VERSION ""

NS_ :

BS_:

BU_: XXX

BO_ 85 CID_ORPMJI: 8 XXX
 SG_ sig_kpehwq : 40|1@1+ (1,0) [0|1] "" XXX
 SG_ sig_occrqr : 56|8@1+ (1,0) [0|255] "" XXX

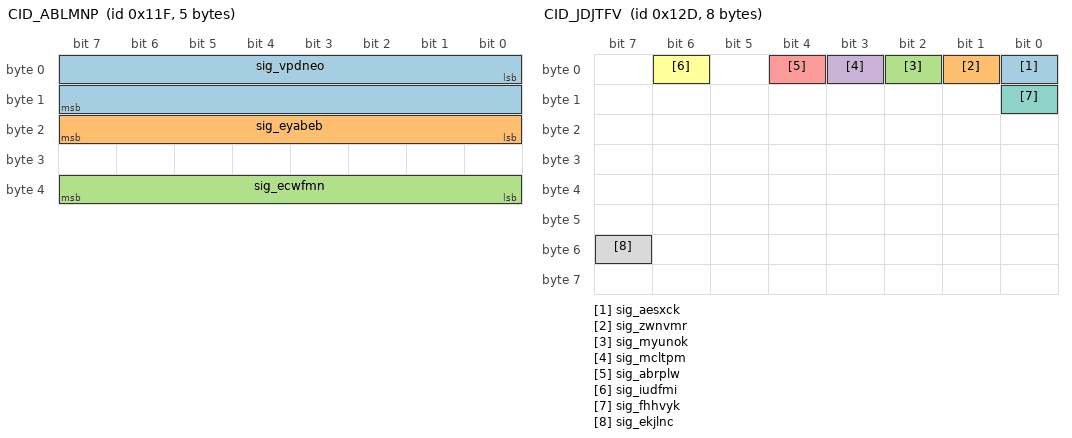
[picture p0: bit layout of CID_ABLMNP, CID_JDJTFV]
BO_ 287 CID_ABLMNP: 5 XXX
 SG_ sig_vpdneo : 0|16@1- (0.1,0) [-450|450] "" XXX
 SG_ sig_eyabeb : 16|8@1+ (4,0) [0|1020] "" XXX
 SG_ sig_ecwfmn : 32|8@1+ (1,0) [0|255] "" XXX

BO_ 289 CID_XTCXCM: 8 XXX
 SG_ sig_tqkhlx : 0|12@1+ (1,0) [0|255] "" XXX

BO_ 301 CID_JDJTFV: 8 XXX
 SG_ sig_aesxck : 0|1@0+ (1,0) [0|1] "" XXX
 SG_ sig_zwnvmr : 1|1@0+ (1,0) [0|1] "" XXX
 SG_ sig_myunok : 2|1@0+ (1,0) [0|1] "" XXX
 SG_ sig_mcltpm : 3|1@0+ (1,0) [0|1] "" XXX
 SG_ sig_abrplw : 4|1@0+ (1,0) [0|1] "" XXX
 SG_ sig_iudfmi : 6|1@0+ (1,0) [0|1] "" XXX
 SG_ sig_fhhvyk : 8|1@0+ (1,0) [0|1] "" XXX
 SG_ sig_ekjlnc : 55|1@0+ (1,0) [0|1] "" XXX

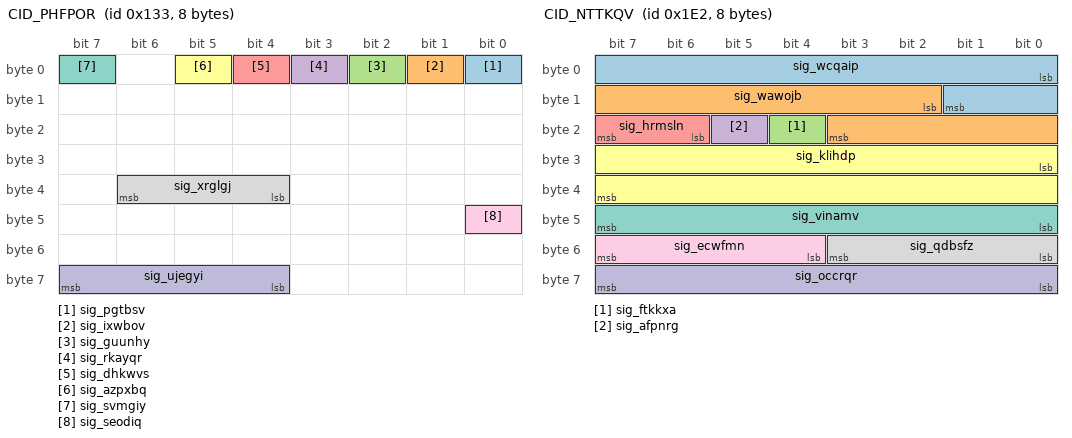
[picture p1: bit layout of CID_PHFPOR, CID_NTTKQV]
BO_ 307 CID_PHFPOR: 8 XXX
 SG_ sig_pgtbsv : 0|1@0+ (1,0) [0|1] "" XXX
 SG_ sig_ixwbov : 1|1@1+ (1,0) [0|1] "" XXX
 SG_ sig_guunhy : 2|1@1+ (1,0) [0|1] "" XXX
 SG_ sig_rkayqr : 3|1@1+ (1,0) [0|1] "" XXX
 SG_ sig_dhkwvs : 4|1@0+ (1,0) [0|1] "" XXX
 SG_ sig_azpxbq : 5|1@0+ (1,0) [0|1] "" XXX
 SG_ sig_svmgiy : 7|1@0+ (1,0) [0|1] "" XXX
 SG_ sig_xrglgj : 36|3@1+ (1,0) [0|7] "" XXX
 SG_ sig_seodiq : 40|1@0+ (1,0) [0|1] "" XXX
 SG_ sig_ujegyi : 63|4@0+ (1,0) [0|15] "" XXX

BO_ 482 CID_NTTKQV: 8 XXX
 SG_ sig_wcqaip : 0|10@1- (0.01,0) [0|5] "" XXX
 SG_ sig_wawojb : 10|10@1- (0.01,0) [-5|0] "" XXX
 SG_ sig_ftkkxa : 20|1@0+ (1,0) [0|1] "" XXX
 SG_ sig_afpnrg : 21|1@0+ (1,0) [0|1] "" XXX
 SG_ sig_hrmsln : 22|2@1+ (1,0) [0|1] "" XXX
 SG_ sig_klihdp : 24|16@1- (0.1,0) [-780|779.9] "" XXX
 SG_ sig_vinamv : 47|8@0+ (1,0) [0|255] "" XXX
 SG_ sig_qdbsfz : 48|4@1+ (1,0) [0|15] "" XXX
 SG_ sig_ecwfmn : 52|4@1+ (1,0) [0|15] "" XXX
 SG_ sig_occrqr : 56|8@1+ (1,0) [0|255] "" XXX

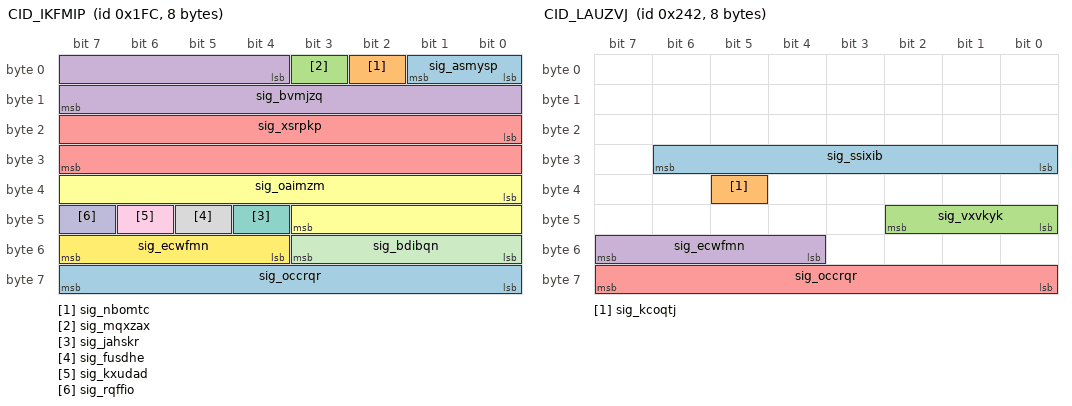
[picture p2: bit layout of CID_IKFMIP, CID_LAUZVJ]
BO_ 508 CID_IKFMIP: 8 XXX
 SG_ sig_asmysp : 0|2@1+ (1,0) [0|1] "" XXX
 SG_ sig_nbomtc : 2|1@1+ (1,0) [0|1] "" XXX
 SG_ sig_mqxzax : 3|1@0+ (1,0) [0|1] "" XXX
 SG_ sig_bvmjzq : 4|12@1- (1,0) [-2048|2047] "" XXX
 SG_ sig_xsrpkp : 16|16@1- (0.1,0) [-780|779.9] "Deg" XXX
 SG_ sig_oaimzm : 32|12@1- (1,0) [0|63] "" XXX
 SG_ sig_jahskr : 44|1@0+ (1,0) [0|1] "" XXX
 SG_ sig_fusdhe : 45|1@1+ (1,0) [0|255] "" XXX
 SG_ sig_kxudad : 46|1@1+ (1,0) [0|1] "" XXX
 SG_ sig_rqffio : 47|1@0+ (1,0) [0|3] "" XXX
 SG_ sig_bdibqn : 48|4@1+ (1,0) [0|15] "" XXX
 SG_ sig_ecwfmn : 52|4@1+ (1,0) [0|15] "" XXX
 SG_ sig_occrqr : 56|8@1+ (1,0) [0|255] "" XXX

BO_ 578 CID_LAUZVJ: 8 XXX
 SG_ sig_ssixib : 30|7@0+ (1,0) [0|127] "" XXX
 SG_ sig_kcoqtj : 37|1@0+ (1,0) [0|1] "" XXX
 SG_ sig_vxvkyk : 40|3@1+ (1,0) [0|7] "" XXX
 SG_ sig_ecwfmn : 55|4@0+ (1,0) [0|15] "" XXX
 SG_ sig_occrqr : 56|8@1+ (1,0) [0|255] "" XXX

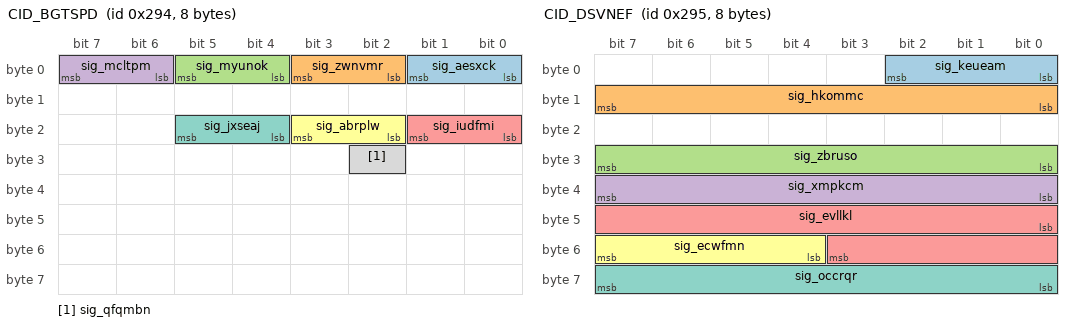
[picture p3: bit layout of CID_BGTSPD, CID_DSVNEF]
BO_ 660 CID_BGTSPD: 8 XXX
 SG_ sig_aesxck : 1|2@0+ (1,0) [0|3] "" XXX
 SG_ sig_zwnvmr : 3|2@0+ (1,0) [0|3] "" XXX
 SG_ sig_myunok : 5|2@0+ (1,0) [0|3] "" XXX
 SG_ sig_mcltpm : 7|2@0+ (1,0) [0|3] "" XXX
 SG_ sig_iudfmi : 17|2@0+ (1,0) [0|3] "" XXX
 SG_ sig_abrplw : 19|2@0+ (1,0) [0|3] "" XXX
 SG_ sig_jxseaj : 21|2@0+ (1,0) [0|3] "" XXX
 SG_ sig_qfqmbn : 26|1@0+ (1,0) [0|1] "" XXX

BO_ 661 CID_DSVNEF: 8 XXX
 SG_ sig_keueam : 2|3@0+ (1,0) [0|7] "" XXX
 SG_ sig_hkommc : 15|8@0+ (1,0) [0|255] "" XXX
 SG_ sig_zbruso : 31|8@0+ (1,0) [0|255] "" XXX
 SG_ sig_xmpkcm : 32|8@1+ (1,0) [0|255] "" XXX
 SG_ sig_evllkl : 40|12@1+ (1,0) [0|255] "" XXX
 SG_ sig_ecwfmn : 52|4@1+ (1,0) [0|15] "" XXX
 SG_ sig_occrqr : 63|8@0+ (1,0) [0|255] "" XXX

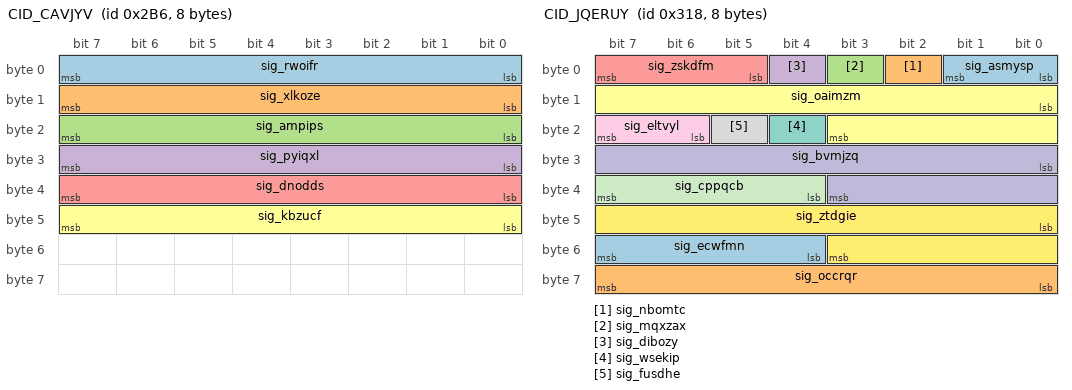
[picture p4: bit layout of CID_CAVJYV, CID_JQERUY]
BO_ 694 CID_CAVJYV: 8 XXX
 SG_ sig_rwoifr : 7|8@0+ (1,0) [0|255] "" XXX
 SG_ sig_xlkoze : 15|8@0+ (1,0) [0|255] "" XXX
 SG_ sig_ampips : 23|8@0+ (1,0) [0|255] "" XXX
 SG_ sig_pyiqxl : 31|8@0+ (1,0) [0|255] "" XXX
 SG_ sig_dnodds : 39|8@0+ (1,0) [0|255] "" XXX
 SG_ sig_kbzucf : 47|8@0+ (1,0) [0|255] "" XXX

BO_ 790 CID_WJEDII: 8 XXX
 SG_ sig_rxfudj : 3|4@0+ (1,0) [0|1] "" XXX
 SG_ sig_mtkdpm : 4|2@1+ (1,0) [0|3] "" XXX
 SG_ sig_cjzzqm : 6|2@1+ (1,0) [0|3] "" XXX
 SG_ sig_cftoca : 8|2@1+ (1,0) [0|3] "" XXX
 SG_ sig_iqbmky : 10|1@1+ (1,0) [0|1] "" XXX
 SG_ sig_kcvkfq : 11|4@1+ (1,0) [0|1] "" XXX
 SG_ sig_qqhjhv : 15|1@0+ (1,0) [0|1] "" XXX
 SG_ sig_klihdp : 16|11@1- (1,0) [-1024|1023] "" XXX
 SG_ sig_ftkkxa : 27|1@1+ (1,0) [0|1] "" XXX
 SG_ sig_afpnrg : 28|1@1+ (1,0) [0|3] "" XXX
 SG_ sig_xrcajq : 29|1@0+ (1,0) [0|1] "" XXX
 SG_ sig_wlxkrd : 30|1@0+ (1,0) [0|1] "" XXX
 SG_ sig_mabznd : 31|1@0+ (1,0) [0|1] "" XXX
 SG_ sig_gksgyc : 32|2@1+ (1,0) [0|3] "" XXX
 SG_ sig_vhlttp : 34|2@1+ (1,0) [0|3] "" XXX
 SG_ sig_iozlfq : 36|4@1+ (1,0) [0|3] "" XXX
 SG_ sig_axlhtm : 40|8@1+ (5,-5) [-5|1270] "" XXX
 SG_ sig_scojim : 49|2@0+ (1,0) [0|3] "" XXX
 SG_ sig_disemo : 51|2@0+ (1,0) [0|3] "" XXX
 SG_ sig_ecwfmn : 52|4@1+ (1,0) [0|15] "" XXX
 SG_ sig_occrqr : 56|8@1+ (1,0) [0|15] "" XXX

BO_ 792 CID_JQERUY: 8 XXX
 SG_ sig_asmysp : 0|2@1+ (1,0) [0|1] "" XXX
 SG_ sig_nbomtc : 2|1@1+ (1,0) [0|1] "" XXX
 SG_ sig_mqxzax : 3|1@1+ (1,0) [0|1] "" XXX
 SG_ sig_dibozy : 4|1@1+ (1,0) [0|1] "" XXX
 SG_ sig_zskdfm : 5|3@1+ (1,0) [0|1] "" XXX
 SG_ sig_oaimzm : 8|12@1- (1,0) [-2048|2047] "" XXX
 SG_ sig_wsekip : 20|1@1+ (1,0) [0|1] "" XXX
 SG_ sig_fusdhe : 21|1@1+ (1,0) [0|1] "" XXX
 SG_ sig_eltvyl : 22|2@1+ (1,0) [0|15] "" XXX
 SG_ sig_bvmjzq : 24|12@1- (1,0) [-2048|2047] "" XXX
 SG_ sig_cppqcb : 36|4@1+ (1,0) [0|15] "" XXX
 SG_ sig_ztdgie : 40|12@1+ (1,0) [0|4095] "" XXX
 SG_ sig_ecwfmn : 52|4@1+ (1,0) [0|15] "" XXX
 SG_ sig_occrqr : 56|8@1+ (1,0) [0|255] "" XXX

BO_ 813 CID_ESBHYA: 8 XXX
 SG_ sig_vfjsnv : 0|9@1+ (0.5,0) [0|255.5] "" XXX
 SG_ sig_aacjof : 9|1@1+ (1,0) [0|1] "" XXX
 SG_ sig_tpaojq : 10|3@1+ (1,0) [0|7] "" XXX
 SG_ sig_czsqxk : 13|3@1+ (1,0) [0|7] "" XXX
 SG_ sig_hikfiq : 16|1@1+ (1,0) [0|1] "" XXX
 SG_ sig_nopkci : 17|1@1+ (1,0) [0|1] "" XXX
 SG_ sig_mqxzax : 18|1@1+ (1,0) [0|1] "" XXX
 SG_ sig_lhbjsc : 19|3@1+ (1,0) [0|1] "" XXX
 SG_ sig_ybafjf : 22|1@0+ (1,0) [0|1] "" XXX
 SG_ sig_ipndvt : 23|1@0+ (1,0) [0|1] "" XXX
 SG_ sig_cftoca : 24|1@1+ (1,0) [0|1] "" XXX
 SG_ sig_bpdkws : 25|7@1+ (1,0) [0|127] "" XXX
 SG_ sig_hisvjs : 32|4@1+ (1,0) [0|15] "" XXX
 SG_ sig_ufwkqt : 36|12@1+ (1,0) [0|4095] "" XXX
 SG_ sig_ecwfmn : 48|4@1+ (1,0) [0|15] "" XXX
 SG_ sig_rxqmhj : 55|4@0+ (1,0) [0|15] "" XXX
 SG_ sig_occrqr : 56|8@1+ (1,0) [0|255] "" XXX

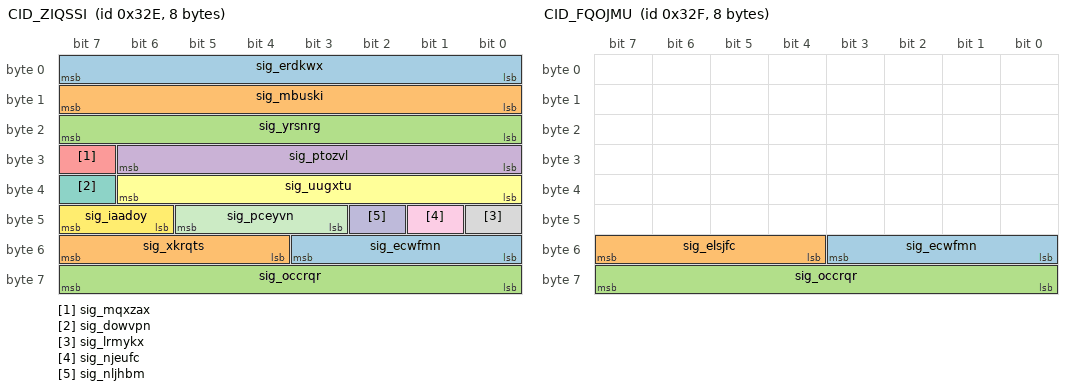
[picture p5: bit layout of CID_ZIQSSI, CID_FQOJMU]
BO_ 814 CID_ZIQSSI: 8 XXX
 SG_ sig_erdkwx : 0|8@1+ (0.05,-5) [-100|155] "" XXX
 SG_ sig_mbuski : 8|8@1+ (0.05,-5) [0|1.26] "" XXX
 SG_ sig_yrsnrg : 16|8@1+ (0.05,-5) [0|1.26] "" XXX
 SG_ sig_ptozvl : 24|7@1+ (0.2,0) [0|12.7] "" XXX
 SG_ sig_mqxzax : 31|1@0+ (1,0) [0|1] "" XXX
 SG_ sig_uugxtu : 32|7@1+ (0.2,-16) [0|12.7] "" XXX
 SG_ sig_dowvpn : 39|1@0+ (1,0) [0|1] "" XXX
 SG_ sig_lrmykx : 40|1@0+ (1,0) [0|1] "" XXX
 SG_ sig_njeufc : 41|1@0+ (1,0) [0|1] "" XXX
 SG_ sig_nljhbm : 42|1@1+ (1,0) [0|3] "" XXX
 SG_ sig_pceyvn : 45|3@0+ (1,0) [0|1] "" XXX
 SG_ sig_iaadoy : 46|2@1+ (1,0) [0|3] "" XXX
 SG_ sig_ecwfmn : 48|4@1+ (1,0) [0|15] "" XXX
 SG_ sig_xkrqts : 55|4@0+ (1,0) [0|15] "" XXX
 SG_ sig_occrqr : 56|8@1+ (1,0) [0|255] "" XXX

BO_ 815 CID_FQOJMU: 8 XXX
 SG_ sig_ecwfmn : 48|4@1+ (1,0) [0|15] "" XXX
 SG_ sig_elsjfc : 55|4@0+ (1,0) [0|15] "" XXX
 SG_ sig_occrqr : 56|8@1+ (1,0) [0|255] "" XXX

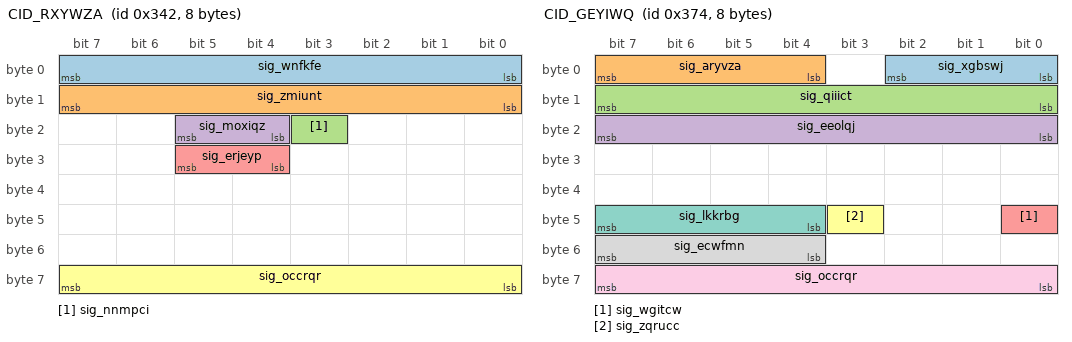
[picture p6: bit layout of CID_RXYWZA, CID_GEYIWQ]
BO_ 834 CID_RXYWZA: 8 XXX
 SG_ sig_wnfkfe : 0|8@1+ (0.01,0) [0|2.55] "" XXX
 SG_ sig_zmiunt : 8|8@1+ (0.01,0) [0|2.55] "" XXX
 SG_ sig_nnmpci : 19|1@1+ (1,0) [0|1] "" XXX
 SG_ sig_moxiqz : 20|2@1+ (1,0) [0|255] "" XXX
 SG_ sig_erjeyp : 28|2@1+ (1,0) [0|1] "" XXX
 SG_ sig_occrqr : 56|8@1+ (1,0) [0|255] "" XXX

BO_ 884 CID_GEYIWQ: 8 MRR
 SG_ sig_xgbswj : 2|3@0+ (1,0) [0|3] "" MRR
 SG_ sig_aryvza : 7|4@0+ (1,0) [0|15] "" MRR
 SG_ sig_qiiict : 15|8@0+ (0.1,-12) [0|255] "" MRR
 SG_ sig_eeolqj : 23|8@0+ (1,-100) [0|255] "" MRR
 SG_ sig_wgitcw : 40|1@0+ (1,0) [0|3] "" MRR
 SG_ sig_zqrucc : 43|1@0+ (1,0) [0|1] "" XXX
 SG_ sig_lkkrbg : 44|4@1+ (1,0) [0|15] "" XXX
 SG_ sig_ecwfmn : 52|4@1+ (1,0) [0|15] "" MRR
 SG_ sig_occrqr : 56|8@1+ (1,0) [0|255] "" MRR

BO_ 944 CID_NLJDVP: 8 XXX
 SG_ sig_pghdef : 1|2@0+ (1,0) [0|3] "" XXX
 SG_ sig_bdtemc : 2|1@0+ (1,0) [0|1] "" XXX
 SG_ sig_ssjzbo : 4|2@0+ (1,0) [0|3] "" XXX
 SG_ sig_scwbbo : 5|1@0+ (1,0) [0|1] "" XXX
 SG_ sig_daaxzt : 6|1@0+ (1,0) [0|1] "" XXX
 SG_ sig_dghjiu : 7|1@0+ (1,0) [0|1] "" XXX
 SG_ sig_zkgvvl : 8|1@0+ (1,0) [0|1] "" XXX
 SG_ sig_jahbgo : 11|3@0+ (1,0) [0|7] "" XXX
 SG_ sig_jdenvn : 12|1@0+ (1,0) [0|1] "" XXX
 SG_ sig_fwtvzd : 14|2@0+ (1,0) [0|3] "" XXX
 SG_ sig_wcszdu : 15|1@0+ (1,0) [0|1] "" XXX
 SG_ sig_dcasqb : 16|1@0+ (1,0) [0|1] "" XXX
 SG_ sig_jxlpuy : 18|2@0+ (1,0) [0|3] "" XXX
 SG_ sig_sbcjai : 19|1@0+ (1,0) [0|1] "" XXX
 SG_ sig_izbunk : 23|4@0+ (1,0) [0|15] "" XXX
 SG_ sig_idffaj : 24|28@1+ (1,0) [0|268435455] "" XXX
 SG_ sig_ecwfmn : 52|4@1+ (1,0) [0|15] "" XXX
 SG_ sig_occrqr : 56|8@1+ (1,0) [0|255] "" XXX

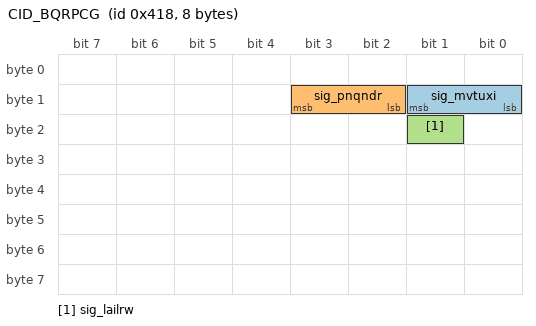
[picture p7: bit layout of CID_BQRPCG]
BO_ 1048 CID_BQRPCG: 8 XXX
 SG_ sig_mvtuxi : 9|2@0+ (1,0) [0|1] "" XXX
 SG_ sig_pnqndr : 11|2@0+ (1,0) [0|1] "" XXX
 SG_ sig_lailrw : 17|1@0+ (1,0) [0|1] "" XXX

VAL_ 578 sig_vxvkyk 4 "D" 2 "R" 3 "N" 1 "P";
VAL_ 790 sig_rxfudj 11 "AutoFullBeamActive" 2 "AutoFullBeamInactive";
VAL_ 790 sig_mtkdpm 0 "GRAY" 1 "GREEN" 2 "YELLOW" 3 "RED";
VAL_ 790 sig_cjzzqm 3 "ALARM_AND_LKA" 2 "LKA" 1 "ALARM" 0 "DISABLE";
VAL_ 790 sig_vhlttp 0 "GRAY" 1 "GREEN" 2 "YELLOW" 3 "RED";
VAL_ 790 sig_scojim 0 "VIBRATION" 1 "AUDIO" 2 "AUDIO_AND_VIBRATION";
VAL_ 792 sig_asmysp 0 "NotReady" 1 "Ready" 2 "Active" 3 "TemporaryFail";
VAL_ 813 sig_tpaojq 4 "4BAR" 3 "3BAR" 2 "2BAR" 1 "1BAR";
VAL_ 813 sig_lhbjsc 0 "OFF" 2 "ACC_ON" 3 "ACC_ACTIVE" 5 "FORCE_ACCEL" 7 "ERROR";
VAL_ 813 sig_bpdkws 36 "ACC_ERROR" 22 "OVERRIDE" 12 "ENGAGE" 8 "DISENGAGE" 20 "ACC_ON" 32 "ACC_OFF" 48 "CHECK_GEAR_D" 16 "FORCE_ACCEL" 0 "NONE";
VAL_ 814 sig_pceyvn 0 "Off" 1 "Passive" 2 "StandBy" 3 "ActiveControl" 4 "BrakeOnly" 5 "Override" 6 "Standstill" 7 "Failure";
VAL_ 814 sig_iaadoy 0 "Softoff" 1 "Fastoff" 2 "Immediateoff" 3 "Initial";
VAL_ 834 sig_moxiqz 2 "SPORT" 1 "ECO" 0 "SNOW";
VAL_ 834 sig_erjeyp 3 "HEV" 2 "FORCE_EV" 1 "EV";
VAL_ 944 sig_ssjzbo 0 "NOTPRESSED" 1 "DOWN_SETSPEED" 3 "UP_RESETSPEED";
